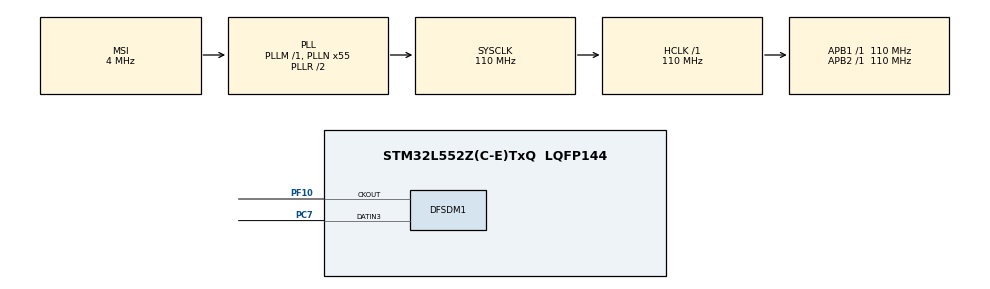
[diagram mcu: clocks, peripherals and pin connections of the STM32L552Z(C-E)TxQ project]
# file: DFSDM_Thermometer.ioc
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DFSDM1.Divider=110
DFSDM1.Filter_injChannel2_FIL0=DFSDM_CHANNEL_2
DFSDM1.Filter_injChannel3_FIL0=DFSDM_CHANNEL_3
DFSDM1.Fosr_FIL0=64
DFSDM1.Iosr_FIL0=64
DFSDM1.Oversampling_CH2=10
DFSDM1.Oversampling_CH3=10
DFSDM1.ScanMode_inj_FIL0=ENABLE
DFSDM1.SincOrder_FIL0=DFSDM_FILTER_SINC3_ORDER
DFSDM1.Trigger_inj_FIL0=DFSDM_FILTER_EXT_TRIGGER
DFSDM1.Type_spi_CH3=DFSDM_CHANNEL_SPI_FALLING
Mcu.Family=STM32L5
Mcu.Name=STM32L552Z(C-E)TxQ
Mcu.Package=LQFP144
NVIC.DFSDM1_FLT0_IRQn=true\:1\:0\:true\:false\:true\:true\:true\:true
NVIC.PriorityGroup=NVIC_PRIORITYGROUP_3
PC7.GPIO_PuPd=GPIO_PULLDOWN
PC7.GPIO_Speed=GPIO_SPEED_FREQ_VERY_HIGH
PC7.Signal=S_DATAIN3DFSDM1
PF10.GPIO_PuPd=GPIO_PULLDOWN
PF10.GPIO_Speed=GPIO_SPEED_FREQ_VERY_HIGH
PF10.Signal=S_CKOUTDFSDM1
ProjectManager.HeapSize=0x200
ProjectManager.StackSize=0x800
ProjectManager.TargetToolchain=EWARM V8.32
RCC.AHBFreq_Value=110000000
RCC.APB1Freq_Value=110000000
RCC.APB1TimFreq_Value=110000000
RCC.APB2Freq_Value=110000000
RCC.APB2TimFreq_Value=110000000
RCC.CortexFreq_Value=110000000
RCC.DFSDMCLockSelection=RCC_DFSDM1CLKSOURCE_SYSCLK
RCC.HCLKFreq_Value=110000000
RCC.HSE_VALUE=16000000
RCC.HSI48_VALUE=48000000
RCC.HSI_VALUE=16000000
RCC.LSE_VALUE=32768
RCC.MSI_VALUE=4000000
RCC.PLLN=55
RCC.SYSCLKFreq_VALUE=110000000
RCC.SYSCLKSource=RCC_SYSCLKSOURCE_PLLCLK
RCC.VCOOutputFreq_Value=220000000
SH.S_CKOUTDFSDM1.0=DFSDM1_CKOUT,PDM_SPI_Input_from_ch23_and_Internal_Clock
SH.S_CKOUTDFSDM1.1=DFSDM1_CKOUT,PDM_SPI_input_from_ch3_and_internal_clock
SH.S_DATAIN3DFSDM1.0=DFSDM1_DATIN3,PDM_SPI_Input_from_ch23_and_Internal_Clock
SH.S_DATAIN3DFSDM1.1=DFSDM1_DATIN3,PDM_SPI_input_from_ch3_and_internal_clock
TIM1.Channel-PWM\ Generation1\ No\ Output=TIM_CHANNEL_1
TIM1.Period=10000
TIM1.Prescaler=10999
TIM1.Pulse-PWM\ Generation1\ No\ Output=5000
TIM1.TIM_MasterOutputTrigger=TIM_TRGO_UPDATE
TIM1.TIM_MasterSlaveMode=TIM_MASTERSLAVEMODE_ENABLE
VP_ICACHE_VS_ICACHE.Mode=DirectMappedCache
VP_PWR_VS_DBSignals.Mode=DisableDeadBatterySignals
VP_TIM1_VS_no_output1.Mode=PWM Generation1 No Output
board=custom

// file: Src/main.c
/* USER CODE BEGIN Header */
/**
  ******************************************************************************
  * @file           : main.c
  * @brief          : Main program body
  ******************************************************************************
  * @attention
  *
  * Copyright (c) 2019 STMicroelectronics.
  * All rights reserved.
  *
  * This software is licensed under terms that can be found in the LICENSE file
  * in the root directory of this software component.
  * If no LICENSE file comes with this software, it is provided AS-IS.
  *
  ******************************************************************************
  */
/* USER CODE END Header */
#include "main.h"

DFSDM_Filter_HandleTypeDef hdfsdm1_filter0;
DFSDM_Channel_HandleTypeDef hdfsdm1_channel2;
DFSDM_Channel_HandleTypeDef hdfsdm1_channel3;

TIM_HandleTypeDef htim1;

/* USER CODE BEGIN PV */
float                        voltageValue = 0;
float                        currentValue = 0;
__IO uint32_t                voltageAvailable = 0;
__IO uint32_t                currentAvailable = 0;
float                        temperature = 0;
/* USER CODE END PV */

void SystemClock_Config(void);
static void MX_GPIO_Init(void);
static void MX_ICACHE_Init(void);
static void MX_DFSDM1_Init(void);
static void MX_TIM1_Init(void);

int main(void)
{
  /* USER CODE BEGIN 1 */
  LCD_UTILS_Drv_t lcdDrv;
  /* USER CODE END 1 */

  /* MCU Configuration--------------------------------------------------------*/

  /* Reset of all peripherals, Initializes the Flash interface and the Systick. */
  HAL_Init();

  /* USER CODE BEGIN Init */
  /* Configure LED5 */
  if (BSP_ERROR_NONE != BSP_LED_Init(LED5))
  {
    Error_Handler();
  }
  /* USER CODE END Init */

  /* Configure the system clock */
  SystemClock_Config();

  /* USER CODE BEGIN SysInit */
  /* Initialize LCD */
  if (BSP_ERROR_NONE != BSP_LCD_Init(0, LCD_ORIENTATION_LANDSCAPE))
  {
    Error_Handler();
  }
  /* USER CODE END SysInit */

  /* Initialize all configured peripherals */
  MX_GPIO_Init();
  MX_ICACHE_Init();
  MX_DFSDM1_Init();
  MX_TIM1_Init();
  /* USER CODE BEGIN 2 */
  /* Link board LCD drivers to UTIL_LCD drivers */
  lcdDrv.DrawBitmap  = BSP_LCD_DrawBitmap;
  lcdDrv.FillRGBRect = BSP_LCD_FillRGBRect;
  lcdDrv.DrawHLine   = BSP_LCD_DrawHLine;
  lcdDrv.DrawVLine   = BSP_LCD_DrawVLine;
  lcdDrv.FillRect    = BSP_LCD_FillRect;
  lcdDrv.GetPixel    = BSP_LCD_ReadPixel;
  lcdDrv.SetPixel    = BSP_LCD_WritePixel;
  lcdDrv.GetXSize    = BSP_LCD_GetXSize;
  lcdDrv.GetYSize    = BSP_LCD_GetYSize;
  lcdDrv.SetLayer    = BSP_LCD_SetActiveLayer;
  lcdDrv.GetFormat   = BSP_LCD_GetFormat;
  UTIL_LCD_SetFuncDriver(&lcdDrv);
  UTIL_LCD_Clear(UTIL_LCD_COLOR_WHITE);

  /* Display ON LCD */
  if (BSP_ERROR_NONE != BSP_LCD_DisplayOn(0))
  {
    Error_Handler();
  }

  UTIL_LCD_SetFont(&Font24);
  UTIL_LCD_SetBackColor(UTIL_LCD_COLOR_WHITE);
  UTIL_LCD_SetTextColor(LCD_COLOR_DARKBLUE);
  UTIL_LCD_DisplayStringAtLine(0, (uint8_t *)"TEMPERATURE :");
  UTIL_LCD_SetTextColor(UTIL_LCD_COLOR_DARKRED);

  /* Start DFSDM conversions */
  if (HAL_OK != HAL_DFSDM_FilterInjectedStart_IT(&hdfsdm1_filter0))
  {
    Error_Handler();
  }

  /* Start timer */
  if (HAL_OK != HAL_TIM_PWM_Start(&htim1, TIM_CHANNEL_1))
  {
    Error_Handler();
  }
  /* USER CODE END 2 */

  /* Infinite loop */
  /* USER CODE BEGIN WHILE */
  while (1)
  {
    /* Waiting current and voltage values available */
    if ((voltageAvailable == 1) && (currentAvailable == 1))
    {
      uint8_t LCDstr[10] = {0};

      /* Compute and display temperature value */
      temperature = ((voltageValue/currentValue) - 100)/0.385f;
      sprintf((char*)LCDstr, "%3.1f oC", temperature);
      UTIL_LCD_DisplayStringAtLine(1, (uint8_t *) LCDstr);

      voltageAvailable = 0;
      currentAvailable = 0;
    }
    /* USER CODE END WHILE */

  }
}

void SystemClock_Config(void)
{
  RCC_OscInitTypeDef RCC_OscInitStruct = {0};
  RCC_ClkInitTypeDef RCC_ClkInitStruct = {0};

  /** Configure the main internal regulator output voltage
  */
  if (HAL_PWREx_ControlVoltageScaling(PWR_REGULATOR_VOLTAGE_SCALE0) != HAL_OK)
  {
    Error_Handler();
  }

  /** Initializes the RCC Oscillators according to the specified parameters
  * in the RCC_OscInitTypeDef structure.
  */
  RCC_OscInitStruct.OscillatorType = RCC_OSCILLATORTYPE_MSI;
  RCC_OscInitStruct.MSIState = RCC_MSI_ON;
  RCC_OscInitStruct.MSICalibrationValue = RCC_MSICALIBRATION_DEFAULT;
  RCC_OscInitStruct.MSIClockRange = RCC_MSIRANGE_6;
  RCC_OscInitStruct.PLL.PLLState = RCC_PLL_ON;
  RCC_OscInitStruct.PLL.PLLSource = RCC_PLLSOURCE_MSI;
  RCC_OscInitStruct.PLL.PLLM = 1;
  RCC_OscInitStruct.PLL.PLLN = 55;
  RCC_OscInitStruct.PLL.PLLP = RCC_PLLP_DIV7;
  RCC_OscInitStruct.PLL.PLLQ = RCC_PLLQ_DIV2;
  RCC_OscInitStruct.PLL.PLLR = RCC_PLLR_DIV2;
  if (HAL_RCC_OscConfig(&RCC_OscInitStruct) != HAL_OK)
  {
    Error_Handler();
  }

  /** Initializes the CPU, AHB and APB buses clocks
  */
  RCC_ClkInitStruct.ClockType = RCC_CLOCKTYPE_HCLK|RCC_CLOCKTYPE_SYSCLK
                              |RCC_CLOCKTYPE_PCLK1|RCC_CLOCKTYPE_PCLK2;
  RCC_ClkInitStruct.SYSCLKSource = RCC_SYSCLKSOURCE_PLLCLK;
  RCC_ClkInitStruct.AHBCLKDivider = RCC_SYSCLK_DIV1;
  RCC_ClkInitStruct.APB1CLKDivider = RCC_HCLK_DIV1;
  RCC_ClkInitStruct.APB2CLKDivider = RCC_HCLK_DIV1;

  if (HAL_RCC_ClockConfig(&RCC_ClkInitStruct, FLASH_LATENCY_5) != HAL_OK)
  {
    Error_Handler();
  }
}

static void MX_DFSDM1_Init(void)
{

  hdfsdm1_filter0.Instance = DFSDM1_Filter0;
  hdfsdm1_filter0.Init.InjectedParam.Trigger = DFSDM_FILTER_EXT_TRIGGER;
  hdfsdm1_filter0.Init.InjectedParam.ScanMode = ENABLE;
  hdfsdm1_filter0.Init.InjectedParam.DmaMode = DISABLE;
  hdfsdm1_filter0.Init.InjectedParam.ExtTrigger = DFSDM_FILTER_EXT_TRIG_TIM1_TRGO;
  hdfsdm1_filter0.Init.InjectedParam.ExtTriggerEdge = DFSDM_FILTER_EXT_TRIG_RISING_EDGE;
  hdfsdm1_filter0.Init.FilterParam.SincOrder = DFSDM_FILTER_SINC3_ORDER;
  hdfsdm1_filter0.Init.FilterParam.Oversampling = 64;
  hdfsdm1_filter0.Init.FilterParam.IntOversampling = 64;
  if (HAL_DFSDM_FilterInit(&hdfsdm1_filter0) != HAL_OK)
  {
    Error_Handler();
  }
  hdfsdm1_channel2.Instance = DFSDM1_Channel2;
  hdfsdm1_channel2.Init.OutputClock.Activation = ENABLE;
  hdfsdm1_channel2.Init.OutputClock.Selection = DFSDM_CHANNEL_OUTPUT_CLOCK_SYSTEM;
  hdfsdm1_channel2.Init.OutputClock.Divider = 110;
  hdfsdm1_channel2.Init.Input.Multiplexer = DFSDM_CHANNEL_EXTERNAL_INPUTS;
  hdfsdm1_channel2.Init.Input.DataPacking = DFSDM_CHANNEL_STANDARD_MODE;
  hdfsdm1_channel2.Init.Input.Pins = DFSDM_CHANNEL_FOLLOWING_CHANNEL_PINS;
  hdfsdm1_channel2.Init.SerialInterface.Type = DFSDM_CHANNEL_SPI_RISING;
  hdfsdm1_channel2.Init.SerialInterface.SpiClock = DFSDM_CHANNEL_SPI_CLOCK_INTERNAL;
  hdfsdm1_channel2.Init.Awd.FilterOrder = DFSDM_CHANNEL_FASTSINC_ORDER;
  hdfsdm1_channel2.Init.Awd.Oversampling = 10;
  hdfsdm1_channel2.Init.Offset = 0;
  hdfsdm1_channel2.Init.RightBitShift = 0x00;
  if (HAL_DFSDM_ChannelInit(&hdfsdm1_channel2) != HAL_OK)
  {
    Error_Handler();
  }
  hdfsdm1_channel3.Instance = DFSDM1_Channel3;
  hdfsdm1_channel3.Init.OutputClock.Activation = ENABLE;
  hdfsdm1_channel3.Init.OutputClock.Selection = DFSDM_CHANNEL_OUTPUT_CLOCK_SYSTEM;
  hdfsdm1_channel3.Init.OutputClock.Divider = 110;
  hdfsdm1_channel3.Init.Input.Multiplexer = DFSDM_CHANNEL_EXTERNAL_INPUTS;
  hdfsdm1_channel3.Init.Input.DataPacking = DFSDM_CHANNEL_STANDARD_MODE;
  hdfsdm1_channel3.Init.Input.Pins = DFSDM_CHANNEL_SAME_CHANNEL_PINS;
  hdfsdm1_channel3.Init.SerialInterface.Type = DFSDM_CHANNEL_SPI_FALLING;
  hdfsdm1_channel3.Init.SerialInterface.SpiClock = DFSDM_CHANNEL_SPI_CLOCK_INTERNAL;
  hdfsdm1_channel3.Init.Awd.FilterOrder = DFSDM_CHANNEL_FASTSINC_ORDER;
  hdfsdm1_channel3.Init.Awd.Oversampling = 10;
  hdfsdm1_channel3.Init.Offset = 0;
  hdfsdm1_channel3.Init.RightBitShift = 0x00;
  if (HAL_DFSDM_ChannelInit(&hdfsdm1_channel3) != HAL_OK)
  {
    Error_Handler();
  }
  if (HAL_DFSDM_FilterConfigInjChannel(&hdfsdm1_filter0, DFSDM_CHANNEL_2|DFSDM_CHANNEL_3) != HAL_OK)
  {
    Error_Handler();
  }

}

static void MX_ICACHE_Init(void)
{

  /** Enable instruction cache in 1-way (direct mapped cache)
  */
  if (HAL_ICACHE_ConfigAssociativityMode(ICACHE_1WAY) != HAL_OK)
  {
    Error_Handler();
  }
  if (HAL_ICACHE_Enable() != HAL_OK)
  {
    Error_Handler();
  }

}

static void MX_TIM1_Init(void)
{

  TIM_MasterConfigTypeDef sMasterConfig = {0};
  TIM_OC_InitTypeDef sConfigOC = {0};
  TIM_BreakDeadTimeConfigTypeDef sBreakDeadTimeConfig = {0};

  htim1.Instance = TIM1;
  htim1.Init.Prescaler = 10999;
  htim1.Init.CounterMode = TIM_COUNTERMODE_UP;
  htim1.Init.Period = 10000;
  htim1.Init.ClockDivision = TIM_CLOCKDIVISION_DIV1;
  htim1.Init.RepetitionCounter = 0;
  htim1.Init.AutoReloadPreload = TIM_AUTORELOAD_PRELOAD_DISABLE;
  if (HAL_TIM_PWM_Init(&htim1) != HAL_OK)
  {
    Error_Handler();
  }
  sMasterConfig.MasterOutputTrigger = TIM_TRGO_UPDATE;
  sMasterConfig.MasterOutputTrigger2 = TIM_TRGO2_RESET;
  sMasterConfig.MasterSlaveMode = TIM_MASTERSLAVEMODE_ENABLE;
  if (HAL_TIMEx_MasterConfigSynchronization(&htim1, &sMasterConfig) != HAL_OK)
  {
    Error_Handler();
  }
  sConfigOC.OCMode = TIM_OCMODE_PWM1;
  sConfigOC.Pulse = 5000;
  sConfigOC.OCPolarity = TIM_OCPOLARITY_HIGH;
  sConfigOC.OCNPolarity = TIM_OCNPOLARITY_HIGH;
  sConfigOC.OCFastMode = TIM_OCFAST_DISABLE;
  sConfigOC.OCIdleState = TIM_OCIDLESTATE_RESET;
  sConfigOC.OCNIdleState = TIM_OCNIDLESTATE_RESET;
  if (HAL_TIM_PWM_ConfigChannel(&htim1, &sConfigOC, TIM_CHANNEL_1) != HAL_OK)
  {
    Error_Handler();
  }
  sBreakDeadTimeConfig.OffStateRunMode = TIM_OSSR_DISABLE;
  sBreakDeadTimeConfig.OffStateIDLEMode = TIM_OSSI_DISABLE;
  sBreakDeadTimeConfig.LockLevel = TIM_LOCKLEVEL_OFF;
  sBreakDeadTimeConfig.DeadTime = 0;
  sBreakDeadTimeConfig.BreakState = TIM_BREAK_DISABLE;
  sBreakDeadTimeConfig.BreakPolarity = TIM_BREAKPOLARITY_HIGH;
  sBreakDeadTimeConfig.BreakFilter = 0;
  sBreakDeadTimeConfig.BreakAFMode = TIM_BREAK_AFMODE_INPUT;
  sBreakDeadTimeConfig.Break2State = TIM_BREAK2_DISABLE;
  sBreakDeadTimeConfig.Break2Polarity = TIM_BREAK2POLARITY_HIGH;
  sBreakDeadTimeConfig.Break2Filter = 0;
  sBreakDeadTimeConfig.Break2AFMode = TIM_BREAK_AFMODE_INPUT;
  sBreakDeadTimeConfig.AutomaticOutput = TIM_AUTOMATICOUTPUT_DISABLE;
  if (HAL_TIMEx_ConfigBreakDeadTime(&htim1, &sBreakDeadTimeConfig) != HAL_OK)
  {
    Error_Handler();
  }

}

static void MX_GPIO_Init(void)
{

  /* GPIO Ports Clock Enable */
  __HAL_RCC_GPIOF_CLK_ENABLE();
  __HAL_RCC_GPIOC_CLK_ENABLE();

}

/* USER CODE BEGIN 4 */
/**
  * @brief  Injected conversion complete callback.
  * @note   In interrupt mode, user has to read conversion value in this function
            using HAL_DFSDM_FilterGetInjectedValue.
  * @param  hdfsdm_filter : DFSDM filter handle.
  * @retval None
  */
void HAL_DFSDM_FilterInjConvCpltCallback(DFSDM_Filter_HandleTypeDef *hdfsdm_filter)
{
  int32_t  convValue;
  uint32_t channel;

  /* read conversion value and corresponding channel */
  convValue = HAL_DFSDM_FilterGetInjectedValue(hdfsdm_filter, &channel);

  if (channel == 2)
  {
    /* current channel */
    currentValue = (float) convValue/(100*64);
    currentAvailable = 1;
  }
  else if (channel == 3)
  {
    /* voltage channel */
    voltageValue = convValue/64;
    voltageAvailable = 1;
  }
}
/* USER CODE END 4 */

void Error_Handler(void)
{
  /* USER CODE BEGIN Error_Handler_Debug */
  while (1)
  {
    /* Toggle LED5 with a period of one second */
    (void) BSP_LED_Toggle(LED5);
    HAL_Delay(1000);
  }
  /* USER CODE END Error_Handler_Debug */
}

#ifdef  USE_FULL_ASSERT
/**
  * @brief  Reports the name of the source file and the source line number
  *         where the assert_param error has occurred.
  * @param  file: pointer to the source file name
  * @param  line: assert_param error line source number
  * @retval None
  */
void assert_failed(uint8_t *file, uint32_t line)
{
  /* USER CODE BEGIN 6 */
  /* User can add his own implementation to report the file name and line number,
     ex: printf("Wrong parameters value: file %s on line %d\r\n", file, line) */
  /* Infinite loop */
  while (1)
  {}
  /* USER CODE END 6 */
}
#endif /* USE_FULL_ASSERT */
